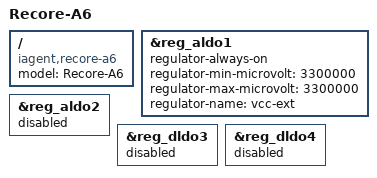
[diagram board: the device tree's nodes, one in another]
// SPDX-License-Identifier: (GPL-2.0+ OR MIT)

/dts-v1/;

#include "sun50i-a64-recore.dtsi"

/ {
	model = "Recore-A6";
	compatible = "iagent,recore-a6", "allwinner,sun50i-a64";
};

&reg_aldo1 {
	regulator-always-on;
	regulator-min-microvolt = <3300000>;
	regulator-max-microvolt = <3300000>;
	regulator-name = "vcc-ext";
};

&reg_aldo2 {
	status = "disabled";
};

&reg_dldo3 {
status = "disabled";
};

&reg_dldo4 {
	status = "disabled";
};
